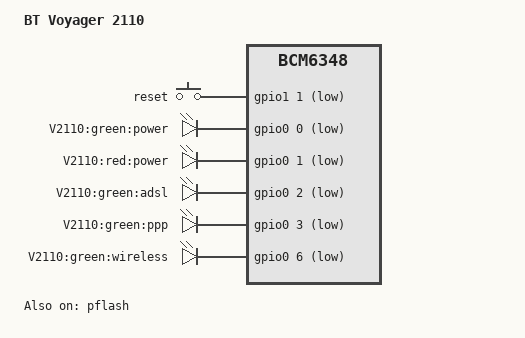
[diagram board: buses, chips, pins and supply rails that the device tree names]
/dts-v1/;

#include "bcm6348.dtsi"

#include <dt-bindings/input/input.h>

/ {
	model = "BT Voyager 2110";
	compatible = "bt,v2110", "brcm,bcm6348";

	gpio-keys-polled {
		compatible = "gpio-keys-polled";
		#address-cells = <1>;
		#size-cells = <0>;
		poll-interval = <20>;
		debounce-interval = <60>;

		reset {
			label = "reset";
			gpios = <&gpio1 1 1>;
			linux,code = <KEY_RESTART>;
		};
	};

	gpio-leds {
		compatible = "gpio-leds";

		power_green {
			label = "V2110:green:power";
			gpios = <&gpio0 0 1>;
		};
		power_red {
			label = "V2110:red:power";
			gpios = <&gpio0 1 1>;
		};
		adsl_green {
			label = "V2110:green:adsl";
			gpios = <&gpio0 2 1>;
		};
		ppp_green {
			label = "V2110:green:ppp";
			gpios = <&gpio0 3 1>;
		};
		wireless_green {
			label = "V2110:green:wireless";
			gpios = <&gpio0 6 1>;
		};
	};
};

&pflash {
	status = "ok";

	linux,part-probe = "bcm63xxpart";

	cfe@0 {
		label = "CFE";
		reg = <0x000000 0x010000>;
		read-only;
	};

	linux@10000 {
		label = "linux";
		reg = <0x010000 0x3e0000>;
	};

	nvram@3f0000 {
		label = "nvram";
		reg = <0x3f0000 0x010000>;
	};
};
